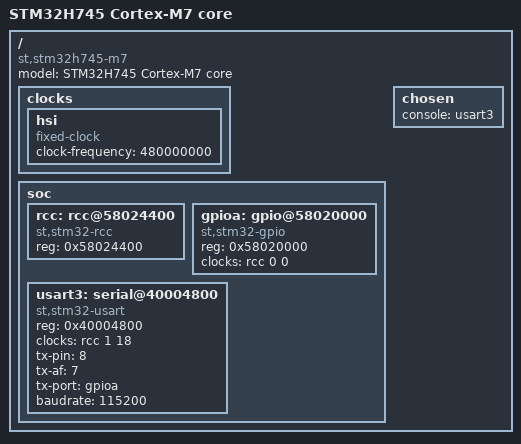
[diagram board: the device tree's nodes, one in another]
/ {
    compatible = "st,stm32h745-m7";
    model = "STM32H745 Cortex-M7 core";

    clocks {
        hsi: hsi {
            compatible = "fixed-clock";
            clock-frequency = <480000000>;  /* M7 runs at 480MHz */
        };
    };

    soc {
        rcc: rcc@58024400 {
            compatible = "st,stm32-rcc";
            reg = <0x58024400>;
        };

        gpioa: gpio@58020000 {
            compatible = "st,stm32-gpio";
            reg = <0x58020000>;
            clocks = <&rcc 0 0>;
        };

        usart3: serial@40004800 {
            compatible = "st,stm32-usart";
            reg = <0x40004800>;
            clocks = <&rcc 1 18>;
            tx-pin = <8>;
            tx-af = <7>;
            tx-port = <&gpioa>;
            baudrate = <115200>;
            status = "okay";
        };
    };

    chosen {
        console = <&usart3>;
    };
};
